# N32F030 register map
File version: 1.0
Registers are 32-bit, read-write, reset 0x0 unless marked. A register's access mark holds for its fields unless they carry their own. Offsets are from the block's base; [hi:lo] are bit positions; {n}, {i} and the like mark numbered series; 'fields as' and 'values as' point back to an identical list.

## ACMP — ACMP Register Map
Base 0x400D0000
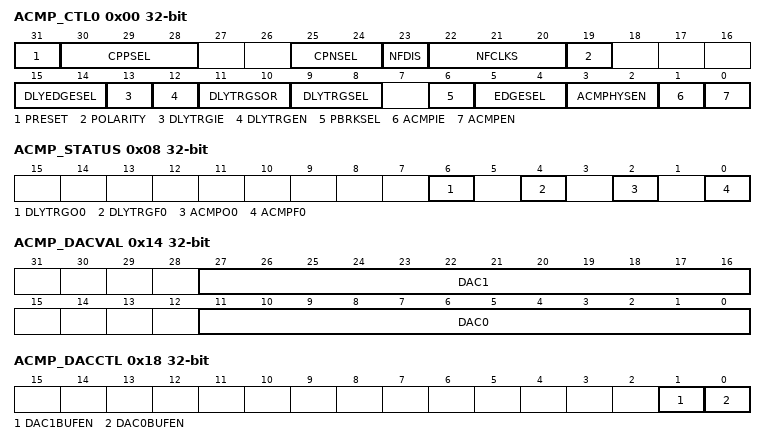
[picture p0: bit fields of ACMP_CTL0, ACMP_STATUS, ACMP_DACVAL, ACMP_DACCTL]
0x00 ACMP_CTL0 — Analog Comparator 0 Control Register
  [31] PRESET — Comparator Result Preset Value
    0=0 for ACMP0 preset value; 1=1 for ACMP0 preset value
  [30:28] CPPSEL — Comparator Positive Input Select
    0=ACMP0_P0 (PB.0); 1=ACMP0_P1 (PB.1); 2=ACMP0_P2 (PB.2); 3=ACMP0_P3 (PC.1); 4=OP1_O (PE.2)
  [25:24] CPNSEL — Comparator Negative Input Select
    0=ACMP0_N (PB.4); 1=Band_Gap; 2=DAC1; 3=DAC0
  [23] NFDIS — Disable Comparator Noise Filter
    0=Noise filter Enabled; 1=Noise filter Disabled
  [22:20] NFCLKS — Noise Filter Clock Pre-divided Selection. To determine the sampling frequency of the Noise Filter clock
    0=PCLK; 1=PCLK / 2; 2=PCLK / 4; 3=PCLK / 8; 4=PCLK/ 16; 5=PCLK / 32; 6=PCLK / 64; 7=PCLK / 256
  [19] POLARITY — Analog Comparator Polarity Control
    0=Analog Comparator normal output; 1=Analog Comparator invert output
  [15:14] DLYEDGESEL — PWM Delay Trigger Interrupt Flag Trigger Edge Detection
    0=Interrupt Flag Trigger Edge Disabled; 1=Rising; 2=Falling; 3=Rising/Falling
  [13] DLYTRGIE — Analog Comparator Delay Trigger Mode Interrupt Enable Control
    0=Analog Comparator Delay Trigger Mode Interrupt Disabled; 1=Analog Comparator Delay Trigger Mode Interrupt Enabled
  [12] DLYTRGEN — Analog Comparator Delay Trigger Mode Enable Control
    0=Analog Comparator Delay Trigger Mode Disabled; 1=Analog Comparator Delay Trigger Mode Enabled
  [11:10] DLYTRGSOR — Analog Comparator Delay Trigger Mode Trigger Source Selection
    0=EPWM_CH0; 1=EPWM_CH2; 2=EPWM_CH4; 3=TMR2_MATCH
  [9:8] DLYTRGSEL — Analog Comparator Delay Trigger Mode Trigger Level Selection
    0=Analog Comparator Delay Trigger Mode Trigger Disabled; 1=High; 2=Low; 3=High/Low
  [6] PBRKSEL — ACMP to EPWM Brake Selection
    0=ACMP Result direct output; 1=ACMP Delay Trigger Result output
  [5:4] EDGESEL — Interrupt Flag Trigger Edge Detection
    values as DLYEDGESEL
  [3:2] ACMPHYSEN — Comparator0 Hysteresis Enable Control
    0=ACMP0 Hysteresis function Disabled (Default); 1=ACMP0 Hysteresis function at comparator0 that the typical range is 20mV; 2=ACMP0 Hysteresis function at comparator0 that the typical range is 90mV; 3=ACMP0 Hysteresis function at comparator0 that the typical range is 150mV
  [1] ACMPIE — Comparator Interrupt Enable Control. Note1: Interrupt is generated if ACMPIE bit is set to '1' after ACMP conversion is finished.
    0=ACMP interrupt function Disabled; 1=ACMP interrupt function Enabled
  [0] ACMPEN — Comparator Enable Control. Note: Comparator output needs to wait 2 us stable time after ACMPEN is set.
    0=Comparator Disabled; 1=Comparator Enabled
0x08 ACMP_STATUS — Analog Comparator Status Register
  [6] DLYTRGO0 — Analog Comparator0 Delay Trigger Mode Comparator Output
  [4] DLYTRGF0 — Comparator0 Flag. This bit is set by hardware whenever the comparator0 output changes state. This will cause an interrupt if DLYTRGIEN set. Write '1' to clear this bit to 0.
  [2] ACMPO0 — Comparator0 Output
  [0] ACMPF0 — Comparator0 Flag. This bit is set by hardware whenever the comparator0 output changes state. This will cause an interrupt if ACMPIE set. Write '1' to clear this bit to 0.
0x10 ACMP_TRGDLY — Analog Comparator Delay Trigger Mode Dleay Register
  [8:0] DELAY — Analog Comparator Delay Trigger Mode Delay cycle(PCLK*cycle)
0x14 ACMP_DACVAL — DAC Register
  [27:16] DAC1 — DAC1 Referance Voltage (VDD x DAC1[11:0]/4096)
  [11:0] DAC0 — DAC0 Referance Voltage (VDD x DAC0[11:0]/4096)
0x18 ACMP_DACCTL — DAC Buffer Control Register
  [1] DAC1BUFEN — DAC1 Output Amplifier Enable Control
    0=Amplifier Disabled; 1=Amplifier Enabled
  [0] DAC0BUFEN — DAC0 Output Amplifier Enable Control
    0=Amplifier Disabled; 1=Amplifier Enabled

## HDIV — HDIV Register Map
Base 0x50014000
{0x0+0x20*i} HDIV_DIVIDEND{i} (i=0..2) — Dividend Source Register
  [31:0] DIVIDEND — Dividend Source. This register is given the dividend of divider before calculation is started.
{0x4+0x20*i} HDIV_DIVISOR{i} reset 0xFFFF (i=0..2) — Divisor Source Resister
  [15:0] DIVISOR — Divisor Source. This register is given the divisor of divider before calculation starts. Note: When this register is written, hardware divider will start calculation.
{0x8+0x20*i} HDIV_QUOTIENT{i} (i=0..2) — Quotient Result Resister
  [31:0] QUOTIENT — Quotient Result. This register holds the quotient result of divider after calculation is completed.
{0xC+0x20*i} HDIV_REM{i} (i=0..2) — Remainder Result Register
  [31:0] REM — Remainder Result. The remainder of hardware divider is 16-bit sign integer (REM[15:0]) with sign extension (REM[31:16]) to 32-bit integer.
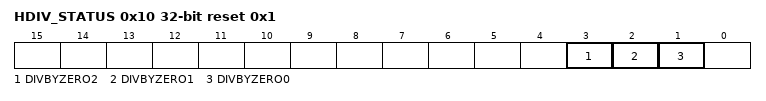
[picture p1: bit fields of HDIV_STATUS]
0x10 HDIV_STATUS ro reset 0x1 — Divider Status Register
  [3] DIVBYZERO2 — Divisor Zero Warning (Read Only). Note: The DIVBYZERO flag is used to indicate divide-by-zero situation and updated whenever HDIV_DIVISOR is written. This bit is read only.
    0=The divisor2 is not 0; 1=The divisor2 is 0
  [2] DIVBYZERO1 — Divisor Zero Warning (Read Only). Note: The DIVBYZERO flag is used to indicate divide-by-zero situation and updated whenever HDIV_DIVISOR is written. This bit is read only.
    0=The divisor1 is not 0; 1=The divisor1 is 0
  [1] DIVBYZERO0 — Divisor Zero Warning (Read Only). Note: The DIVBYZERO flag is used to indicate divide-by-zero situation and updated whenever HDIV_DIVISOR is written. This bit is read only.
    0=The divisor0 is not 0; 1=The divisor0 is 0

## OP — OP Register Map
Base 0x400F0000
0x04 OP_CTL — OP Amplifier Control Register
  [1] OP1EN — Output Amplifier1 Enable Control. Note: The OP output needs to wait stable 20s after OPEN is first set.
    0=Amplifier Disabled; 1=Amplifier Enabled
